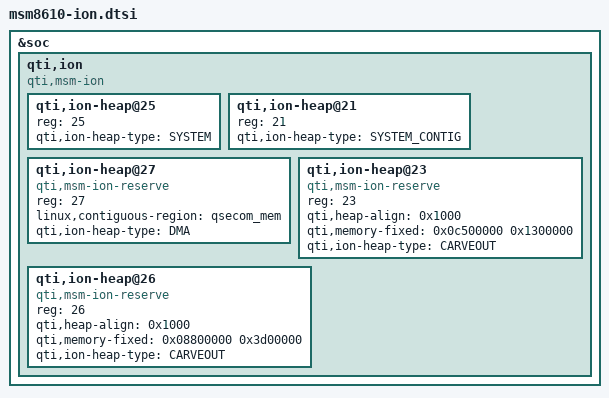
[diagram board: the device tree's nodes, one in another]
/* Copyright (c) 2012-2013, The Linux Foundation. All rights reserved.
 *
 * This program is free software; you can redistribute it and/or modify
 * it under the terms of the GNU General Public License version 2 and
 * only version 2 as published by the Free Software Foundation.
 *
 * This program is distributed in the hope that it will be useful,
 * but WITHOUT ANY WARRANTY; without even the implied warranty of
 * MERCHANTABILITY or FITNESS FOR A PARTICULAR PURPOSE.  See the
 * GNU General Public License for more details.
 */

&soc {
	qti,ion {
		compatible = "qti,msm-ion";
		#address-cells = <1>;
		#size-cells = <0>;

		qti,ion-heap@25 {
			reg = <25>;
			qti,ion-heap-type = "SYSTEM";
		};

		qti,ion-heap@21 {
			reg = <21>;
			qti,ion-heap-type = "SYSTEM_CONTIG";
		};

		qti,ion-heap@27 { /* QSECOM HEAP */
			compatible = "qti,msm-ion-reserve";
			reg = <27>;
			linux,contiguous-region = <&qsecom_mem>;
			qti,ion-heap-type = "DMA";
		};

		qti,ion-heap@23 { /* OTHER PIL HEAP */
			compatible = "qti,msm-ion-reserve";
			reg = <23>;
			qti,heap-align = <0x1000>;
			qti,memory-fixed = <0x0c500000 0x1300000>;
			qti,ion-heap-type = "CARVEOUT";
		};

		qti,ion-heap@26 { /* MODEM HEAP */
			compatible = "qti,msm-ion-reserve";
			reg = <26>;
			qti,heap-align = <0x1000>;
			qti,memory-fixed = <0x08800000 0x3d00000>;
			qti,ion-heap-type = "CARVEOUT";
		};

	};
};

